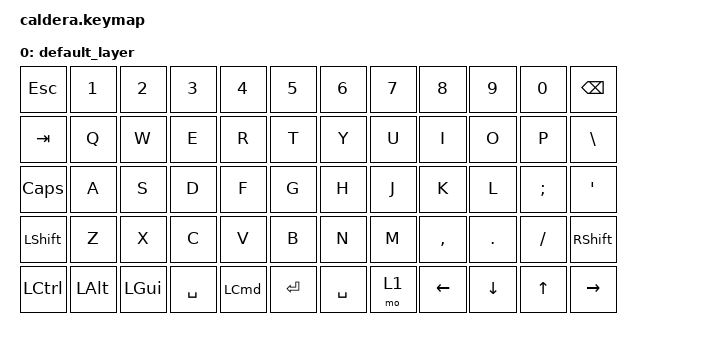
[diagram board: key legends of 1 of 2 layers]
#include <behaviors.dtsi>
#include <dt-bindings/zmk/bt.h>
#include <dt-bindings/zmk/keys.h>

/ {
    keymap {
        compatible = "zmk,keymap";

        default_layer {
            // ---------------------------------------------------------------------------------
            // |  ESC |  1  |  2  |  3  |  4  |  5  |     |  6  |  7  |  8  |  9  |  0  | BKSP |
            // |  TAB |  Q  |  W  |  E  |  R  |  T  |     |  Y  |  U  |  I  |  O  |  P  |  \   |
            // | CAPS |  A  |  S  |  D  |  F  |  G  |     |  H  |  J  |  K  |  L  |  ;  | APOS |
            // | SHFT |  Z  |  X  |  C  |  V  |  B  |     |  N  |  M  |  ,  |  .  |  /  | SHFT |
            // | CTRL | ALT | GUI | SPC | CMD | ENT |     | SPC | LOW |LARW |DARW |UARW | RARW |

            bindings = <
&kp ESCAPE  &kp N1    &kp N2    &kp N3     &kp N4            &kp N5       &kp N6     &kp N7  &kp N8          &kp N9    &kp N0        &kp BSPC
&kp TAB     &kp Q     &kp W     &kp E      &kp R             &kp T        &kp Y      &kp U   &kp I           &kp O     &kp P         &kp BSLH
&kp CAPS    &kp A     &kp S     &kp D      &kp F             &kp G        &kp H      &kp J   &kp K           &kp L     &kp SEMI      &kp APOS
&kp LSHFT   &kp Z     &kp X     &kp C      &kp V             &kp B        &kp N      &kp M   &kp COMMA       &kp DOT   &kp FSLH      &kp RIGHT_SHIFT
&kp LCTRL   &kp LALT  &kp LGUI  &kp SPACE  &kp LEFT_COMMAND  &kp ENTER    &kp SPACE  &mo 1   &kp LEFT_ARROW  &kp DOWN  &kp UP_ARROW  &kp RIGHT
            >;
        };

        lower_layer {
            // ------------------------------------------------------------------------------------------------------------
            // | GRVE  |  BT1  |  BT2  |  BT3  |  BT4  |  BT5  |          |       |       |       |       |       | BTCLR |
            // |       |       |       | LBRC  | RBRC  |       |          |       |       |       |       |       |       |
            // |       |       |       | LPAR  | RPAR  |       |          |       | LBKT  | RBKT  |   -   |   =   |       |
            // |       |       |       |       |       |       |          |       |       |       |       |       |       |

            bindings = <
&kp GRAVE  &bt BT_SEL 0  &bt BT_SEL 1  &bt BT_SEL 2    &bt BT_SEL 3     &bt BT_SEL 4    &trans  &trans    &trans    &trans     &trans     &bt BT_CLR
&trans     &trans        &trans        &kp LEFT_BRACE  &kp RIGHT_BRACE  &trans          &trans  &trans    &trans    &trans     &trans     &trans
&trans     &trans        &trans        &kp LPAR        &kp RPAR         &trans          &trans  &kp LBKT  &kp RBKT  &kp MINUS  &kp EQUAL  &trans
&trans     &trans        &trans        &trans          &trans           &trans          &trans  &trans    &trans    &trans     &trans     &trans
            >;
        };
    };
};

